AUTOSAR XML (schema 00047)
package /Svc_FiM
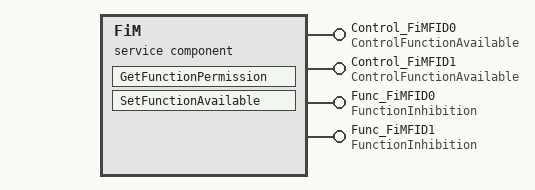
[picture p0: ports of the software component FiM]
  service sw component type FiM
    4 x provide port:
      Control_FiMFID0: server-com-spec{operation=SetFunctionAvailable, queue-length=1}, provided-interface=ControlFunctionAvailable  # This port provides the Supervision interface of �뜝�릳alueAttribute�뜝占� to a SWC.
      Control_FiMFID1: server-com-spec{operation=SetFunctionAvailable, queue-length=1}, provided-interface=ControlFunctionAvailable  # This port provides the Supervision interface of �뜝�릳alueAttribute�뜝占� to a SWC.
      Func_FiMFID0: server-com-spec{operation=GetFunctionPermission, queue-length=1}, provided-interface=FunctionInhibition  # This port provides the Supervision interface of �뜝�릳alueAttribute�뜝占� to a SWC.
      Func_FiMFID1: server-com-spec{operation=GetFunctionPermission, queue-length=1}, provided-interface=FunctionInhibition  # This port provides the Supervision interface of �뜝�릳alueAttribute�뜝占� to a SWC.
    behavior SwcInternalBehavior: handle-termination-and-restart=NO-SUPPORT, included-data-type-set=data-type=[FiM_ConfigType, FiM_FunctionIdType]
      4 x operation invoked event:
        OIE_Func_FiMFID0_FiMFID0_GetFunctionPermission: start-on-event=GetFunctionPermission, operation=Func_FiMFID0.GetFunctionPermission
        OIE_Func_FiMFID0_FiMFID0_SetFunctionAvailable: start-on-event=SetFunctionAvailable, operation=Control_FiMFID0.SetFunctionAvailable
        OIE_Func_FiMFID1_FiMFID1_GetFunctionPermission: start-on-event=GetFunctionPermission, operation=Func_FiMFID1.GetFunctionPermission
        OIE_Func_FiMFID1_FiMFID1_SetFunctionAvailable: start-on-event=SetFunctionAvailable, operation=Control_FiMFID1.SetFunctionAvailable
      port-api-options:
        {enable-take-address=false, indirect-api=false, port-defined-argument-value{value=0, value-type=FiM_FunctionIdType}, port=Func_FiMFID0}
        {enable-take-address=false, indirect-api=false, port-defined-argument-value{value=0, value-type=FiM_FunctionIdType}, port=Control_FiMFID0}
        {enable-take-address=false, indirect-api=false, port-defined-argument-value{value=1, value-type=FiM_FunctionIdType}, port=Func_FiMFID1}
        {enable-take-address=false, indirect-api=false, port-defined-argument-value{value=1, value-type=FiM_FunctionIdType}, port=Control_FiMFID1}
      runnable GetFunctionPermission: can-enter-exclusive-area=[REQUEST_EVENTID_PROTECTION, REQUEST_FID_PROTECTION], can-be-invoked-concurrently=true, symbol=FiM_GetFunctionPermission
      runnable SetFunctionAvailable: can-enter-exclusive-area=[REQUEST_EVENTID_PROTECTION, REQUEST_FID_PROTECTION], can-be-invoked-concurrently=true, symbol=FiM_SetFunctionAvailable
package /Svc_FiM/ClientServerInterfaces
  client server interface ControlFunctionAvailable: is-service=true, service-kind=FUNCTION-INHIBITION-MANAGER
    operation SetFunctionAvailable: possible-error=[ControlFunctionAvailable/E_NOT_OK, ControlFunctionAvailable/E_OK]
      arg Availability: type=boolean, direction=IN
    error E_NOT_OK: error-code=1
    error E_OK: error-code=0
  client server interface FunctionInhibition: is-service=true, service-kind=FUNCTION-INHIBITION-MANAGER
    operation GetFunctionPermission: possible-error=[FunctionInhibition/E_NOT_OK, FunctionInhibition/E_OK]
      arg Permission: type=boolean, direction=OUT
    error E_NOT_OK: error-code=1
    error E_OK: error-code=0
package /Svc_FiM/ImplementationDataTypes
  impl type FiM_ConfigType: category=VALUE, base-type=uint8, type-emitter=FiM.h
  impl type FiM_FunctionIdType: category=VALUE, base-type=uint8, data-constr=uint8
